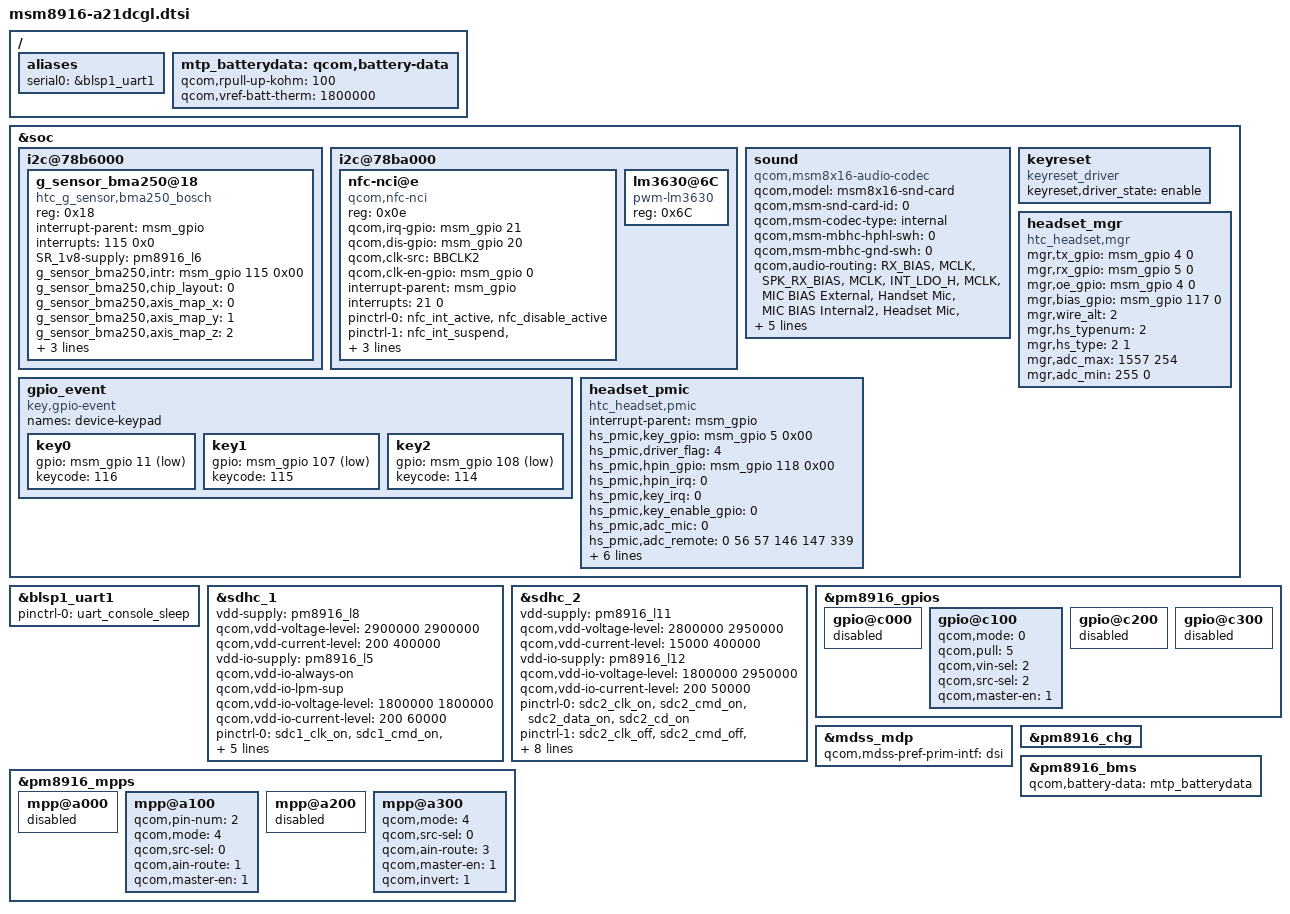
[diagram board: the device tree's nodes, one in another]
/* Copyright (c) 2014, The Linux Foundation. All rights reserved.
 *
 * This program is free software; you can redistribute it and/or modify
 * it under the terms of the GNU General Public License version 2 and
 * only version 2 as published by the Free Software Foundation.
 *
 * This program is distributed in the hope that it will be useful,
 * but WITHOUT ANY WARRANTY; without even the implied warranty of
 * MERCHANTABILITY or FITNESS FOR A PARTICULAR PURPOSE.  See the
 * GNU General Public License for more details.
 */

#include "msm8916.dtsi"
#include "msm8916-pinctrl.dtsi"
#include "msm8916-camera-sensor-a11.dtsi"
#include "dsi-panel-a21.dtsi"
#include "msm8916-touch-a21-config.dtsi"

/ {
	aliases {
		serial0 = &blsp1_uart1;
	};
};

&soc {
	i2c@78b6000 {
		g_sensor_bma250@18 {
			compatible = "htc_g_sensor,bma250_bosch";
			reg = <0x18>;
			interrupt-parent = <&msm_gpio>;
			interrupts = <115 0x0>;
			SR_1v8-supply = <&pm8916_l6>;
			g_sensor_bma250,intr        = <&msm_gpio 115 0x00>;
			g_sensor_bma250,chip_layout = <0>;
			g_sensor_bma250,axis_map_x  = <0>;
			g_sensor_bma250,axis_map_y  = <1>;
			g_sensor_bma250,axis_map_z  = <2>;
			g_sensor_bma250,negate_x    = <0>;
			g_sensor_bma250,negate_y    = <1>;
			g_sensor_bma250,negate_z    = <1>;
		};
	};

	i2c@78ba000 { /* BLSP1 QUP6 */
		nfc-nci@e {
			compatible = "qcom,nfc-nci";
			reg = <0x0e>;
			qcom,irq-gpio = <&msm_gpio 21 0x00>;
			qcom,dis-gpio = <&msm_gpio 20 0x00>;
			qcom,clk-src = "BBCLK2";
			qcom,clk-en-gpio = <&msm_gpio 0 0x00>;
			interrupt-parent = <&msm_gpio>;
			interrupts = <21 0>;
			interrupt-names = "nfc_irq";
			pinctrl-names = "nfc_active","nfc_suspend";
			pinctrl-0 = <&nfc_int_active &nfc_disable_active>;
			pinctrl-1 = <&nfc_int_suspend &nfc_disable_suspend>;
			qcom,clk-gpio = <&pm8916_gpios 2 0>;
			clocks = <&clock_rpm clk_bb_clk2>;
			clock-names = "ref_clk";
		};
	};

	i2c@78ba000 { /* BLSP1 QUP6 */
		lm3630@6C {
			compatible = "pwm-lm3630";
			reg = <0x6C>;
		};
	};

	sound {
		compatible = "qcom,msm8x16-audio-codec";
		qcom,model = "msm8x16-snd-card";
		qcom,msm-snd-card-id = <0>;
		qcom,msm-codec-type = "internal";
		qcom,msm-mbhc-hphl-swh = <0>;
		qcom,msm-mbhc-gnd-swh = <0>;
		qcom,audio-routing =
			"RX_BIAS", "MCLK",
			"SPK_RX_BIAS", "MCLK",
			"INT_LDO_H", "MCLK",
			"MIC BIAS External", "Handset Mic",
			"MIC BIAS Internal2", "Headset Mic",
			"MIC BIAS External", "Secondary Mic",
			"AMIC1", "MIC BIAS External",
			"AMIC2", "MIC BIAS Internal2",
			"AMIC3", "MIC BIAS External";
		pinctrl-names = "cdc_pdm_lines_act",
				"cdc_pdm_lines_sus";
		pinctrl-0 = <&cdc_pdm_lines_act>;
		pinctrl-1 = <&cdc_pdm_lines_sus>;
	};
};

&blsp1_uart1 {
	status = "ok";
	pinctrl-names = "default";
	pinctrl-0 = <&uart_console_sleep>;
};

&soc {
	gpio_event {
	compatible = "key,gpio-event";
	names = "device-keypad";
	//clr_gpio = <&msm_gpio 34 0>;
	//cmcc_disable_reset = <1>;

		key0 {
			gpio    = <&msm_gpio 11 3>;
			keycode = <116>;	//pwr
			//pull = <1>;		//0=pull up, 1=no pull
		};
		key1 {
			gpio    = <&msm_gpio 107 3>;
			keycode = <115>;	//vUP
		};
		key2 {
			gpio    = <&msm_gpio 108 3>;
			keycode = <114>;	//vDN
		};
	};

	keyreset {
		compatible = "keyreset_driver";
		keyreset,driver_state = "enable";
	};

	headset_mgr {
		compatible   = "htc_headset,mgr";
		mgr,tx_gpio  = <&msm_gpio 4 0>;//Pin 4 =NA
		mgr,rx_gpio  = <&msm_gpio 5 0>;
		mgr,oe_gpio  = <&msm_gpio 4 0>;//Pin 4 =NA
		mgr,bias_gpio  = <&msm_gpio 117 0>;
		mgr,wire_alt = <2>;
		mgr,hs_typenum   = <2>;
		mgr,hs_type      = <2 1>;
		mgr,adc_max      = <1557 254>;
		mgr,adc_min      = <255 0>;
	};

	headset_pmic {
		compatible = "htc_headset,pmic";
		interrupt-parent = <&msm_gpio>;
		hs_pmic,key_gpio 	= <&msm_gpio 5 0x00>;
		hs_pmic,driver_flag     = <4>;
		hs_pmic,hpin_gpio       = <&msm_gpio 118 0x00>;
		hs_pmic,hpin_irq        = <0>;
		hs_pmic,key_irq         = <0>;
		hs_pmic,key_enable_gpio = <0>;
		hs_pmic,adc_mic         = <0>;
		hs_pmic,adc_remote      = <0 56 57 146 147 339>;
		hs_pmic,adc_channel	= <19>;		//mpp4
		hs_pmic,adc_mpp         = <0>;
		hs_pmic,adc_amux        = <0>;
		hs_pmic,hs_controller   = <0>;
		hs_pmic,hs_switch       = <0>;
		qcom,headset-vadc	= <&pm8916_vadc>;
	};

//	headset_onewire {
//		compatible = "htc_headset,1wire";
//		hs_1wire,tx_level_shift_en = <&msm_gpio 3 0x00>;
//		hs_1wire,one_wire_remote = <0x7E 0x7F 0x7D 0x7F 0x7B 0x7F>;
//		hs_1wire,onewire_tty_dev = "ttyHSL1";
//	};
};

&sdhc_1 {
	vdd-supply = <&pm8916_l8>;
	qcom,vdd-voltage-level = <2900000 2900000>;
	qcom,vdd-current-level = <200 400000>;

	vdd-io-supply = <&pm8916_l5>;
	qcom,vdd-io-always-on;
	qcom,vdd-io-lpm-sup;
	qcom,vdd-io-voltage-level = <1800000 1800000>;
	qcom,vdd-io-current-level = <200 60000>;

	pinctrl-names = "active", "sleep";
	pinctrl-0 = <&sdc1_clk_on &sdc1_cmd_on &sdc1_data_on>;
	pinctrl-1 = <&sdc1_clk_off &sdc1_cmd_off &sdc1_data_off>;
	htc,slot-type = <0>;
	qcom,nonremovable;

	status = "ok";
};

&sdhc_2 {
	vdd-supply = <&pm8916_l11>;
	qcom,vdd-voltage-level = <2800000 2950000>;
	qcom,vdd-current-level = <15000 400000>;

	vdd-io-supply = <&pm8916_l12>;
	qcom,vdd-io-voltage-level = <1800000 2950000>;
	qcom,vdd-io-current-level = <200 50000>;

	pinctrl-names = "active", "sleep";
	pinctrl-0 = <&sdc2_clk_on &sdc2_cmd_on &sdc2_data_on &sdc2_cd_on>;
	pinctrl-1 = <&sdc2_clk_off &sdc2_cmd_off &sdc2_data_off &sdc2_cd_off>;

	#address-cells = <0>;
	interrupt-parent = <&sdhc_2>;
	interrupts = <0 1 2>;
	#interrupt-cells = <1>;
	interrupt-map-mask = <0xffffffff>;
	interrupt-map = <0 &intc 0 125 0
			1 &intc 0 221 0
			2 &msm_gpio 38 0>;
	interrupt-names = "hc_irq", "pwr_irq", "status_irq";
	cd-gpios = <&msm_gpio 38 0x1>;
	htc,slot-type = <1>;

	status = "ok";
};

&pm8916_mpps {
	mpp@a000 { /* MPP 1 */
		/* VDD_PX */
		status = "disabled";
	};

	mpp@a100 { /* MPP 2 */
		/* HR LED */
		qcom,pin-num = <2>;
                qcom,mode      = <4>;   //QPNP_PIN_MODE_AIN
                qcom,src-sel   = <0>;   //QPNP_PIN_SEL_FUNC_CONSTANT
                qcom,ain-route = <1>;   //QPNP_PIN_AIN_AMUX_CH8
                qcom,master-en = <1>;   //ENABLE FEATURE
	};

	mpp@a200 { /* MPP 3 */
		/* VREF DAC */
		status = "disabled";
	};

	mpp@a300 { /* MPP 4 */
		/* Headset Remote Sensor used*/
		qcom,mode      = <4>;  //QPNP_PIN_MODE_AIN
		qcom,src-sel   = <0>;  //QPNP_PIN_SEL_FUNC_CONSTANT
		qcom,ain-route = <3>;  //QPNP_PIN_AIN_AMUX_CH
		qcom,master-en = <1>;  //ENABLE FEATURE
		qcom,invert = <1>;
	};
};

&pm8916_gpios {
	gpio@c000 { /* GPIO 1 */
		/* Battery UICC Alarm */
		status = "disabled";
	};

	gpio@c100 { /* GPIO 2 */
		/* NFC_CLK_REQ */
		qcom,mode = <0>; /* QPNP_PIN_MODE_DIG_IN */
		qcom,pull = <5>; /* QPNP_PIN_PULL_NO */
		qcom,vin-sel = <2>; /* QPNP_PIN_VIN2 */
		qcom,src-sel = <2>; /* QPNP_PIN_SEL_FUNC_1 */
		qcom,master-en = <1>;
	};

	gpio@c200 { /* GPIO 3 */
		/* External regulator control for WTR */
		status = "disabled";
	};

	gpio@c300 { /* GPIO 4 */
		/* External regulator control for APC */
		status = "disabled";
	};
};

&mdss_mdp {
	qcom,mdss-pref-prim-intf = "dsi";
};

&pm8916_chg {
	status = "ok";
};

/ {
	mtp_batterydata: qcom,battery-data {
		qcom,rpull-up-kohm = <100>;
		qcom,vref-batt-therm = <1800000>;

		#include "batterydata-a11-8x16-id1.dtsi"
	};
};

&pm8916_bms {
	status = "ok";
	qcom,battery-data = <&mtp_batterydata>;
};
